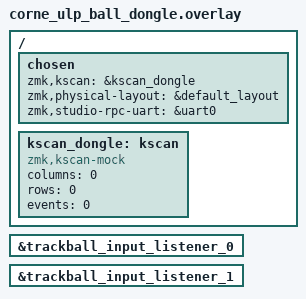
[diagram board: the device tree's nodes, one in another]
#include <dt-bindings/zmk/matrix_transform.h>

#include "corne_ulp_ball-trackball.dtsi"
#include "corne_ulp_ball-layouts.dtsi"

/ {
    chosen {
        zmk,kscan = &kscan_dongle;
        zmk,physical-layout = &default_layout;
        zmk,studio-rpc-uart = &uart0;
    };

    kscan_dongle: kscan {
        compatible = "zmk,kscan-mock";
        columns = <0>;
        rows = <0>;
        events = <0>;
    };
};

&trackball_input_listener_0 {
    status = "okay";
};

&trackball_input_listener_1 {
    status = "okay";
};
